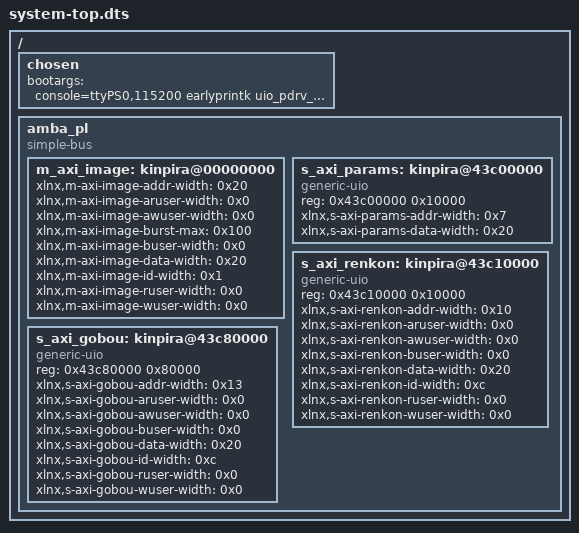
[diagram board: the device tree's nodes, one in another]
/dts-v1/;
/include/ "system-conf.dtsi"
/ {
	chosen {
		bootargs = "console=ttyPS0,115200 earlyprintk uio_pdrv_genirq.of_id=generic-uio";
        };

	amba_pl: amba_pl {
		#address-cells = <1>;
		#size-cells = <1>;
		compatible = "simple-bus";
		ranges ;
		m_axi_image: kinpira@00000000 {
			xlnx,m-axi-image-addr-width = <0x20>;
			xlnx,m-axi-image-aruser-width = <0x0>;
			xlnx,m-axi-image-awuser-width = <0x0>;
			xlnx,m-axi-image-burst-max = <0x100>;
			xlnx,m-axi-image-buser-width = <0x0>;
			xlnx,m-axi-image-data-width = <0x20>;
			xlnx,m-axi-image-id-width = <0x1>;
			xlnx,m-axi-image-ruser-width = <0x0>;
			xlnx,m-axi-image-wuser-width = <0x0>;
		};
		s_axi_params: kinpira@43c00000 {
			compatible = "generic-uio";
			reg = <0x43c00000 0x10000>;
			xlnx,s-axi-params-addr-width = <0x7>;
			xlnx,s-axi-params-data-width = <0x20>;
		};
		s_axi_renkon: kinpira@43c10000 {
			compatible = "generic-uio";
			reg = <0x43c10000 0x10000>;
			xlnx,s-axi-renkon-addr-width = <0x10>;
			xlnx,s-axi-renkon-aruser-width = <0x0>;
			xlnx,s-axi-renkon-awuser-width = <0x0>;
			xlnx,s-axi-renkon-buser-width = <0x0>;
			xlnx,s-axi-renkon-data-width = <0x20>;
			xlnx,s-axi-renkon-id-width = <0xc>;
			xlnx,s-axi-renkon-ruser-width = <0x0>;
			xlnx,s-axi-renkon-wuser-width = <0x0>;
		};
		s_axi_gobou: kinpira@43c80000 {
			compatible = "generic-uio";
			reg = <0x43c80000 0x80000>;
			xlnx,s-axi-gobou-addr-width = <0x13>;
			xlnx,s-axi-gobou-aruser-width = <0x0>;
			xlnx,s-axi-gobou-awuser-width = <0x0>;
			xlnx,s-axi-gobou-buser-width = <0x0>;
			xlnx,s-axi-gobou-data-width = <0x20>;
			xlnx,s-axi-gobou-id-width = <0xc>;
			xlnx,s-axi-gobou-ruser-width = <0x0>;
			xlnx,s-axi-gobou-wuser-width = <0x0>;
		};
	};
};

